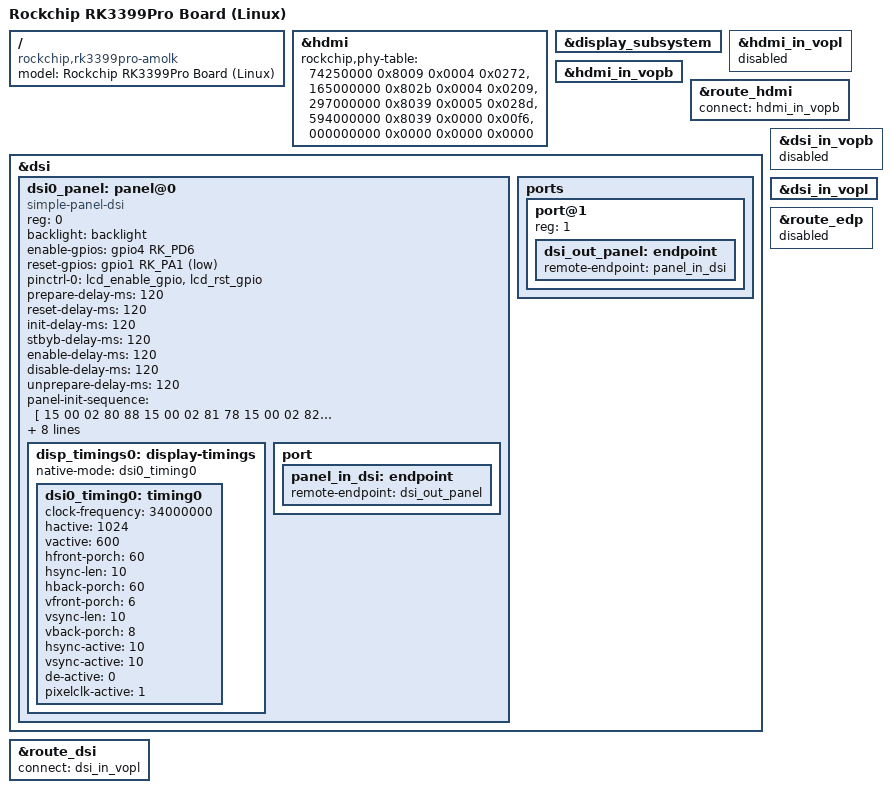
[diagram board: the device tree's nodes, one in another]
/dts-v1/;
#include "rk3399pro-amolk.dtsi"
#include "rk3399-linux.dtsi"

/ {
	compatible = "rockchip,rk3399pro-amolk",
				 "rockchip,rk3399pro-amolk-linux",
				 "rockchip,rk3399pro";
	model = "Rockchip RK3399Pro Board (Linux)";
};

&hdmi {
	#sound-dai-cells = <0>;
	rockchip,phy-table =
		<74250000  0x8009 0x0004 0x0272>,
		<165000000 0x802b 0x0004 0x0209>,
		<297000000 0x8039 0x0005 0x028d>,
		<594000000 0x8039 0x0000 0x00f6>,
		<000000000 0x0000 0x0000 0x0000>;
	status = "okay";
};

&display_subsystem {
	status = "okay";
};

&hdmi_in_vopl {
	status = "disabled";
};

&hdmi_in_vopb {
	status = "okay";
};

&route_hdmi {
	status = "okay";
	connect = <&hdmi_in_vopb>;
};

&dsi {
	status = "okay";
	#address-cells = <1>;
	#size-cells = <0>;

	/*
    dsi0_panel: panel@0 {
		reg = <0>;
		status = "okay";
		backlight = <&backlight>;
		compatible = "vekatech,vklcd07", "fitipower,ek79007ad";
		reset-gpios = <&gpio1 RK_PA1 GPIO_ACTIVE_LOW>;
		switch-gpios = <&gpio4 RK_PD6 GPIO_ACTIVE_HIGH>;
		pinctrl-names = "default";
		pinctrl-0 = <&lcd_enable_gpio>, <&lcd_rst_gpio>;
		lcd-model = "vklcd07";
		dsi-lanes = <4>;
		power-supply = <&vcc5v0_sys>;

		port {
			panel_in_dsi: endpoint {
				remote-endpoint = <&dsi_out_panel>;
			};
		};
	};
	*/
    dsi0_panel: panel@0 {
		status = "okay";
		compatible = "simple-panel-dsi";
		reg = <0>;
		backlight = <&backlight>;
		enable-gpios = <&gpio4 RK_PD6 GPIO_ACTIVE_HIGH>;
		reset-gpios = <&gpio1 RK_PA1 GPIO_ACTIVE_LOW>;
		pinctrl-names = "default";
		pinctrl-0 = <&lcd_enable_gpio>, <&lcd_rst_gpio>;

		prepare-delay-ms = <120>;
		reset-delay-ms = <120>;
		init-delay-ms = <120>;
		stbyb-delay-ms = <120>;
		enable-delay-ms = <120>;
		disable-delay-ms = <120>;
		unprepare-delay-ms = <120>;

		panel-init-sequence = [
			15 00 02 80 88
			15 00 02 81 78
			15 00 02 82 84
			15 00 02 83 88
			15 00 02 84 A8
			15 00 02 85 83
			15 00 02 86 88
			15 00 02 b2 10
		];

		/*
		panel-init-sequence = [
			15 00 02 B0 80
			15 00 02 B1 00
			15 00 02 B2 30
			15 00 02 B3 00
			15 00 02 80 AC
			15 00 02 81 B8
			15 00 02 82 09
			15 00 02 83 78
			15 00 02 84 7F
			15 00 02 85 BB
			15 00 02 86 70
			05 78 01 11
			05 1E 01 29
		];
		*/

		panel-exit-sequence = [
			05 00 01 28
			05 00 01 10
		];

		width-mm = <154>;
		height-mm = <86>;

		dsi,flags = <(
			  MIPI_DSI_MODE_VIDEO | MIPI_DSI_MODE_VIDEO_SYNC_PULSE |
			  MIPI_DSI_MODE_LPM | MIPI_DSI_MODE_VIDEO_HSE
			// MIPI_DSI_MODE_VIDEO |
			// MIPI_DSI_MODE_VIDEO_BURST |
			// MIPI_DSI_MODE_LPM
			// MIPI_DSI_MODE_EOT_PACKET
		)>;
			// MIPI_DSI_MODE_VIDEO_SYNC_PULSE |
			// MIPI_DSI_MODE_LPM
		dsi,format = <MIPI_DSI_FMT_RGB888>;
		dsi,lanes  = <4>;

		disp_timings0: display-timings {
			native-mode = <&dsi0_timing0>;

			dsi0_timing0: timing0 {
				clock-frequency = <34000000>;
				hactive = <1024>;
				vactive = <600>;
				hfront-porch = <60>;
				hsync-len = <10>;
				hback-porch = <60>;
				vfront-porch = <6>;
				vsync-len = <10>;
				vback-porch = <8>;
				hsync-active = <10>;
				vsync-active = <10>;
				de-active = <0>;
				pixelclk-active = <1>;
			};
		};

		port {
			panel_in_dsi: endpoint {
				remote-endpoint = <&dsi_out_panel>;
			};
		};
	};

	ports {
		#address-cells = <1>;
		#size-cells = <0>;

		port@1 {
			reg = <1>;

			dsi_out_panel: endpoint {
				remote-endpoint = <&panel_in_dsi>;
			};
		};
	};
};

&dsi_in_vopb {
	status = "disabled";
};

&dsi_in_vopl {
	status = "okay";
};

&route_dsi {
	status = "okay";
	connect = <&dsi_in_vopl>;
};

&route_edp {
	status = "disabled";
};
